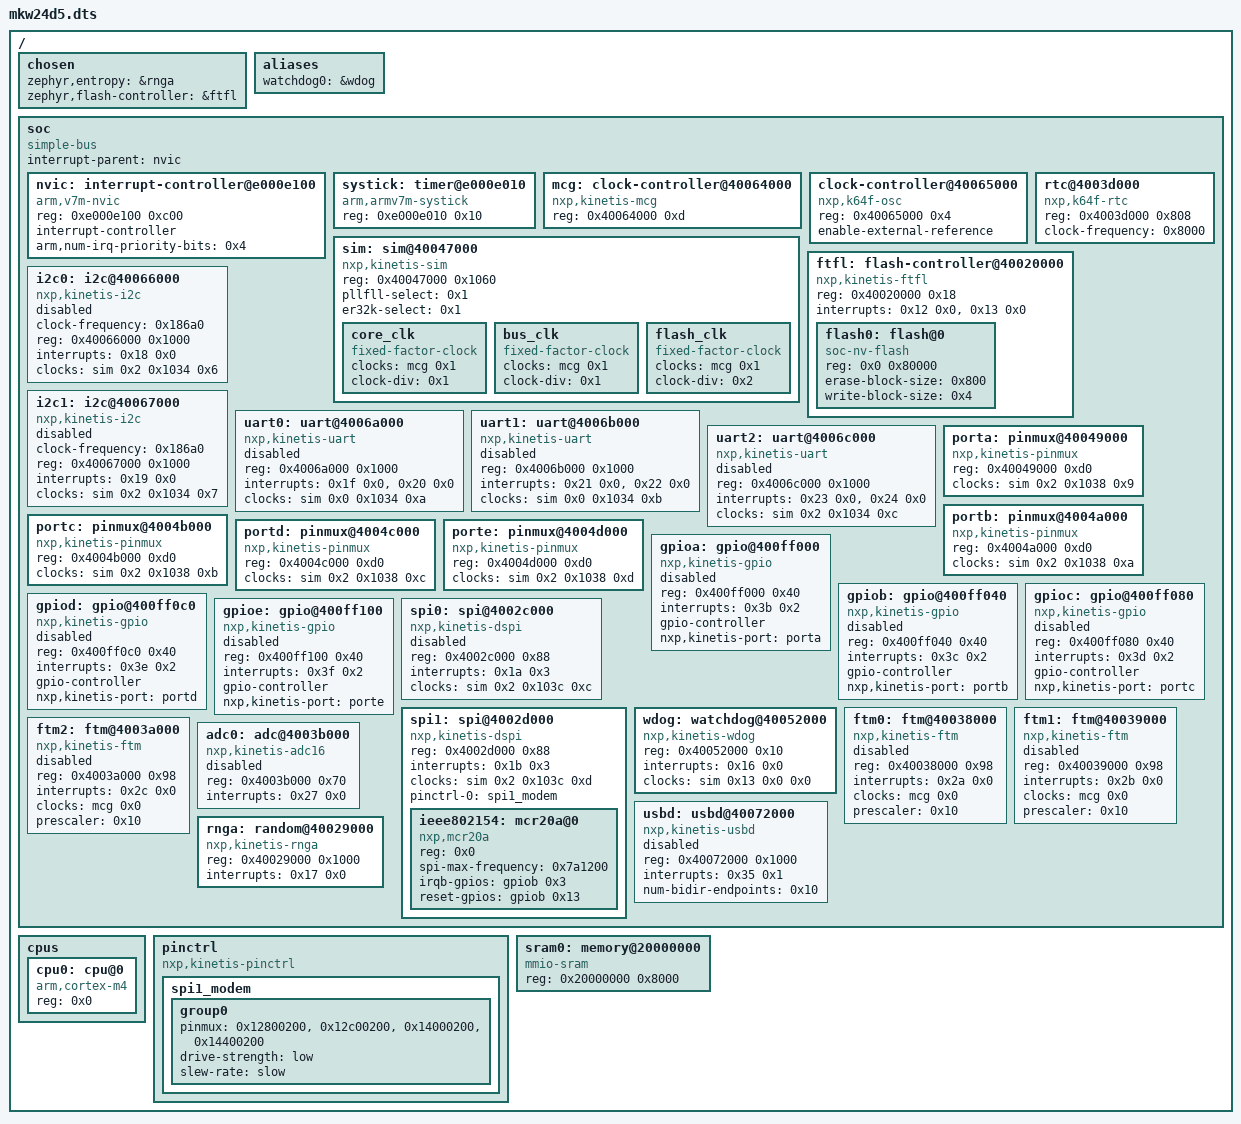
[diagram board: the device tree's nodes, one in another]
/dts-v1/;

/ {
	#address-cells = < 0x1 >;
	#size-cells = < 0x1 >;
	chosen {
		zephyr,entropy = &rnga;
		zephyr,flash-controller = &ftfl;
	};
	aliases {
		watchdog0 = &wdog;
	};
	soc {
		#address-cells = < 0x1 >;
		#size-cells = < 0x1 >;
		compatible = "simple-bus";
		interrupt-parent = < &nvic >;
		ranges;
		nvic: interrupt-controller@e000e100 {
			#address-cells = < 0x1 >;
			compatible = "arm,v7m-nvic";
			reg = < 0xe000e100 0xc00 >;
			interrupt-controller;
			#interrupt-cells = < 0x2 >;
			arm,num-irq-priority-bits = < 0x4 >;
			phandle = < 0x1 >;
		};
		systick: timer@e000e010 {
			compatible = "arm,armv7m-systick";
			reg = < 0xe000e010 0x10 >;
		};
		mcg: clock-controller@40064000 {
			compatible = "nxp,kinetis-mcg";
			reg = < 0x40064000 0xd >;
			#clock-cells = < 0x1 >;
			phandle = < 0x2 >;
		};
		clock-controller@40065000 {
			compatible = "nxp,k64f-osc";
			reg = < 0x40065000 0x4 >;
			enable-external-reference;
		};
		rtc@4003d000 {
			compatible = "nxp,k64f-rtc";
			reg = < 0x4003d000 0x808 >;
			clock-frequency = < 0x8000 >;
		};
		sim: sim@40047000 {
			compatible = "nxp,kinetis-sim";
			reg = < 0x40047000 0x1060 >;
			#clock-cells = < 0x3 >;
			pllfll-select = < 0x1 >;
			er32k-select = < 0x1 >;
			phandle = < 0x3 >;
			core_clk {
				compatible = "fixed-factor-clock";
				clocks = < &mcg 0x1 >;
				clock-div = < 0x1 >;
				#clock-cells = < 0x0 >;
			};
			bus_clk {
				compatible = "fixed-factor-clock";
				clocks = < &mcg 0x1 >;
				clock-div = < 0x1 >;
				#clock-cells = < 0x0 >;
			};
			flash_clk {
				compatible = "fixed-factor-clock";
				clocks = < &mcg 0x1 >;
				clock-div = < 0x2 >;
				#clock-cells = < 0x0 >;
			};
		};
		ftfl: flash-controller@40020000 {
			compatible = "nxp,kinetis-ftfl";
			reg = < 0x40020000 0x18 >;
			interrupts = < 0x12 0x0 >, < 0x13 0x0 >;
			interrupt-names = "command-complete", "read-collision";
			status = "okay";
			#address-cells = < 0x1 >;
			#size-cells = < 0x1 >;
			flash0: flash@0 {
				compatible = "soc-nv-flash";
				reg = < 0x0 0x80000 >;
				erase-block-size = < 0x800 >;
				write-block-size = < 0x4 >;
			};
		};
		i2c0: i2c@40066000 {
			compatible = "nxp,kinetis-i2c";
			clock-frequency = < 0x186a0 >;
			#address-cells = < 0x1 >;
			#size-cells = < 0x0 >;
			reg = < 0x40066000 0x1000 >;
			interrupts = < 0x18 0x0 >;
			clocks = < &sim 0x2 0x1034 0x6 >;
			status = "disabled";
		};
		i2c1: i2c@40067000 {
			compatible = "nxp,kinetis-i2c";
			clock-frequency = < 0x186a0 >;
			#address-cells = < 0x1 >;
			#size-cells = < 0x0 >;
			reg = < 0x40067000 0x1000 >;
			interrupts = < 0x19 0x0 >;
			clocks = < &sim 0x2 0x1034 0x7 >;
			status = "disabled";
		};
		uart0: uart@4006a000 {
			compatible = "nxp,kinetis-uart";
			reg = < 0x4006a000 0x1000 >;
			interrupts = < 0x1f 0x0 >, < 0x20 0x0 >;
			interrupt-names = "status", "error";
			clocks = < &sim 0x0 0x1034 0xa >;
			status = "disabled";
		};
		uart1: uart@4006b000 {
			compatible = "nxp,kinetis-uart";
			reg = < 0x4006b000 0x1000 >;
			interrupts = < 0x21 0x0 >, < 0x22 0x0 >;
			interrupt-names = "status", "error";
			clocks = < &sim 0x0 0x1034 0xb >;
			status = "disabled";
		};
		uart2: uart@4006c000 {
			compatible = "nxp,kinetis-uart";
			reg = < 0x4006c000 0x1000 >;
			interrupts = < 0x23 0x0 >, < 0x24 0x0 >;
			interrupt-names = "status", "error";
			clocks = < &sim 0x2 0x1034 0xc >;
			status = "disabled";
		};
		porta: pinmux@40049000 {
			compatible = "nxp,kinetis-pinmux";
			reg = < 0x40049000 0xd0 >;
			clocks = < &sim 0x2 0x1038 0x9 >;
			phandle = < 0x4 >;
		};
		portb: pinmux@4004a000 {
			compatible = "nxp,kinetis-pinmux";
			reg = < 0x4004a000 0xd0 >;
			clocks = < &sim 0x2 0x1038 0xa >;
			phandle = < 0x5 >;
		};
		portc: pinmux@4004b000 {
			compatible = "nxp,kinetis-pinmux";
			reg = < 0x4004b000 0xd0 >;
			clocks = < &sim 0x2 0x1038 0xb >;
			phandle = < 0x6 >;
		};
		portd: pinmux@4004c000 {
			compatible = "nxp,kinetis-pinmux";
			reg = < 0x4004c000 0xd0 >;
			clocks = < &sim 0x2 0x1038 0xc >;
			phandle = < 0x7 >;
		};
		porte: pinmux@4004d000 {
			compatible = "nxp,kinetis-pinmux";
			reg = < 0x4004d000 0xd0 >;
			clocks = < &sim 0x2 0x1038 0xd >;
			phandle = < 0x8 >;
		};
		gpioa: gpio@400ff000 {
			compatible = "nxp,kinetis-gpio";
			status = "disabled";
			reg = < 0x400ff000 0x40 >;
			interrupts = < 0x3b 0x2 >;
			gpio-controller;
			#gpio-cells = < 0x2 >;
			nxp,kinetis-port = < &porta >;
		};
		gpiob: gpio@400ff040 {
			compatible = "nxp,kinetis-gpio";
			status = "disabled";
			reg = < 0x400ff040 0x40 >;
			interrupts = < 0x3c 0x2 >;
			gpio-controller;
			#gpio-cells = < 0x2 >;
			nxp,kinetis-port = < &portb >;
			phandle = < 0xa >;
		};
		gpioc: gpio@400ff080 {
			compatible = "nxp,kinetis-gpio";
			status = "disabled";
			reg = < 0x400ff080 0x40 >;
			interrupts = < 0x3d 0x2 >;
			gpio-controller;
			#gpio-cells = < 0x2 >;
			nxp,kinetis-port = < &portc >;
		};
		gpiod: gpio@400ff0c0 {
			compatible = "nxp,kinetis-gpio";
			status = "disabled";
			reg = < 0x400ff0c0 0x40 >;
			interrupts = < 0x3e 0x2 >;
			gpio-controller;
			#gpio-cells = < 0x2 >;
			nxp,kinetis-port = < &portd >;
		};
		gpioe: gpio@400ff100 {
			compatible = "nxp,kinetis-gpio";
			status = "disabled";
			reg = < 0x400ff100 0x40 >;
			interrupts = < 0x3f 0x2 >;
			gpio-controller;
			#gpio-cells = < 0x2 >;
			nxp,kinetis-port = < &porte >;
		};
		spi0: spi@4002c000 {
			compatible = "nxp,kinetis-dspi";
			reg = < 0x4002c000 0x88 >;
			interrupts = < 0x1a 0x3 >;
			clocks = < &sim 0x2 0x103c 0xc >;
			status = "disabled";
			#address-cells = < 0x1 >;
			#size-cells = < 0x0 >;
		};
		spi1: spi@4002d000 {
			compatible = "nxp,kinetis-dspi";
			reg = < 0x4002d000 0x88 >;
			interrupts = < 0x1b 0x3 >;
			clocks = < &sim 0x2 0x103c 0xd >;
			#address-cells = < 0x1 >;
			#size-cells = < 0x0 >;
			pinctrl-0 = < &spi1_modem >;
			pinctrl-names = "default";
			ieee802154: mcr20a@0 {
				compatible = "nxp,mcr20a";
				reg = < 0x0 >;
				spi-max-frequency = < 0x7a1200 >;
				irqb-gpios = < &gpiob 0x3 0x0 >;
				reset-gpios = < &gpiob 0x13 0x0 >;
				status = "okay";
			};
		};
		wdog: watchdog@40052000 {
			compatible = "nxp,kinetis-wdog";
			reg = < 0x40052000 0x10 >;
			interrupts = < 0x16 0x0 >;
			clocks = < &sim 0x13 0x0 0x0 >;
		};
		ftm0: ftm@40038000 {
			compatible = "nxp,kinetis-ftm";
			reg = < 0x40038000 0x98 >;
			interrupts = < 0x2a 0x0 >;
			clocks = < &mcg 0x0 >;
			prescaler = < 0x10 >;
			status = "disabled";
		};
		ftm1: ftm@40039000 {
			compatible = "nxp,kinetis-ftm";
			reg = < 0x40039000 0x98 >;
			interrupts = < 0x2b 0x0 >;
			clocks = < &mcg 0x0 >;
			prescaler = < 0x10 >;
			status = "disabled";
		};
		ftm2: ftm@4003a000 {
			compatible = "nxp,kinetis-ftm";
			reg = < 0x4003a000 0x98 >;
			interrupts = < 0x2c 0x0 >;
			clocks = < &mcg 0x0 >;
			prescaler = < 0x10 >;
			status = "disabled";
		};
		adc0: adc@4003b000 {
			compatible = "nxp,kinetis-adc16";
			reg = < 0x4003b000 0x70 >;
			interrupts = < 0x27 0x0 >;
			status = "disabled";
			#io-channel-cells = < 0x1 >;
		};
		usbd: usbd@40072000 {
			compatible = "nxp,kinetis-usbd";
			reg = < 0x40072000 0x1000 >;
			interrupts = < 0x35 0x1 >;
			interrupt-names = "usb_otg";
			num-bidir-endpoints = < 0x10 >;
			status = "disabled";
		};
		rnga: random@40029000 {
			compatible = "nxp,kinetis-rnga";
			reg = < 0x40029000 0x1000 >;
			status = "okay";
			interrupts = < 0x17 0x0 >;
		};
	};
	cpus {
		#address-cells = < 0x1 >;
		#size-cells = < 0x0 >;
		cpu0: cpu@0 {
			device_type = "cpu";
			compatible = "arm,cortex-m4";
			reg = < 0x0 >;
		};
	};
	pinctrl: pinctrl {
		compatible = "nxp,kinetis-pinctrl";
		status = "okay";
		spi1_modem: spi1_modem {
			phandle = < 0x9 >;
			group0 {
				pinmux = < 0x12800200 >, < 0x12c00200 >, < 0x14000200 >, < 0x14400200 >;
				drive-strength = "low";
				slew-rate = "slow";
			};
		};
	};
	sram0: memory@20000000 {
		compatible = "mmio-sram";
		reg = < 0x20000000 0x8000 >;
	};
};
